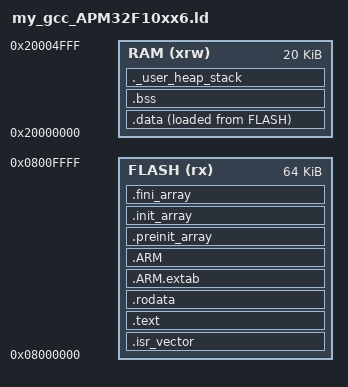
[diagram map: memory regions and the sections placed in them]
/* Entry Point */
ENTRY(Reset_Handler)

/* For stack pointer */
_end_stack = ORIGIN(RAM) + LENGTH(RAM);
/* Used to check that there is enough RAM left */
_heap_size = 0x200; /* Heap Size (in Bytes) */
_stack_size = 1k; /* Stack Size (in Bytes) */

MEMORY
{
  FLASH (rx)  : ORIGIN = 0x08000000, LENGTH = 64k
  RAM (xrw)   : ORIGIN = 0x20000000, LENGTH = 20k
}

SECTIONS
{
  .isr_vector :
  {
    . = ALIGN(4);
    KEEP(*(.isr_vector))
    . = ALIGN(4);
  } >FLASH

  .text :
  {
    . = ALIGN(4);
    *(.text)
    *(.text*)
    *(.glue_7)
    *(.glue_7t)
    *(.eh_frame)

    KEEP (*(.init))
    KEEP (*(.fini))

    . = ALIGN(4);
    _etext = .;
  } >FLASH

  .rodata :
  {
    . = ALIGN(4);
    *(.rodata)
    *(.rodata*)
    . = ALIGN(4);
  } >FLASH

  .ARM.extab   : { *(.ARM.extab* .gnu.linkonce.armextab.*) } >FLASH
  .ARM : {
    __exidx_start = .;
    *(.ARM.exidx*)
    __exidx_end = .;
  } >FLASH

  .preinit_array     :
  {
    PROVIDE_HIDDEN (__preinit_array_start = .);
    KEEP (*(.preinit_array*))
    PROVIDE_HIDDEN (__preinit_array_end = .);
  } >FLASH
  .init_array :
  {
    PROVIDE_HIDDEN (__init_array_start = .);
    KEEP (*(SORT(.init_array.*)))
    KEEP (*(.init_array*))
    PROVIDE_HIDDEN (__init_array_end = .);
  } >FLASH
  .fini_array :
  {
    PROVIDE_HIDDEN (__fini_array_start = .);
    KEEP (*(SORT(.fini_array.*)))
    KEEP (*(.fini_array*))
    PROVIDE_HIDDEN (__fini_array_end = .);
  } >FLASH

  _sdata_lma = LOADADDR(.data);
  .data :
  {
    . = ALIGN(4);
    _sdata = .;
    *(.data)
    *(.data*)

    . = ALIGN(4);
    _edata = .;
  } >RAM AT> FLASH


  . = ALIGN(4);
  .bss :
  {

    _sbss = .;
    __bss_start__ = _sbss;
    *(.bss)
    *(.bss*)
    *(COMMON)

    . = ALIGN(4);
    _ebss = .;
    __bss_end__ = _ebss;
  } >RAM

  ._user_heap_stack :
  {
    . = ALIGN(8);
    PROVIDE ( end = . );
    PROVIDE ( _end = . );
    . = . + _heap_size;
    . = . + _stack_size;
    . = ALIGN(8);
  } >RAM

  /DISCARD/ :
  {
    libc.a ( * )
    libm.a ( * )
    libgcc.a ( * )
  }

  .ARM.attributes 0 : { *(.ARM.attributes) }
}
